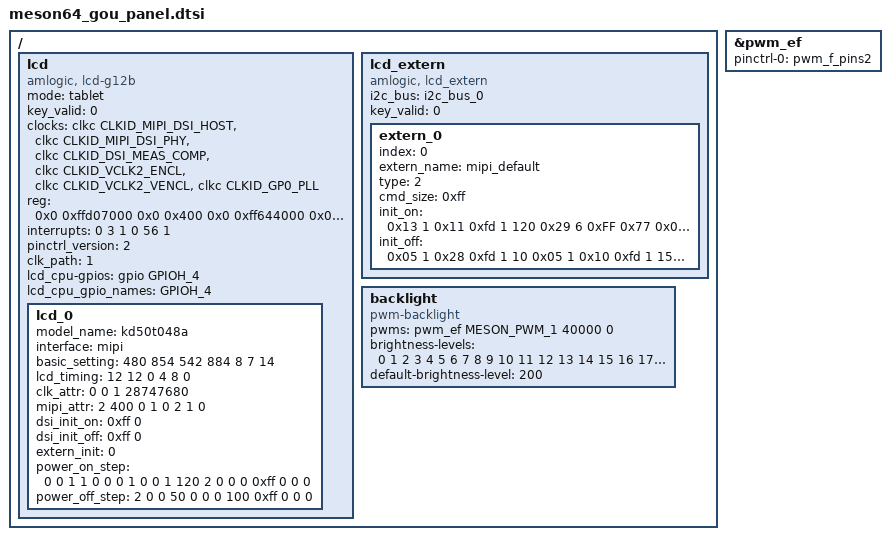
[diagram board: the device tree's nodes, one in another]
/*
 * arch/arm64/boot/dts/amlogic/meson64_gou_panel.dtsi
 *
 * Copyright (C) 2021 Hardkernel Co,. Ltd. All rights reserved.
 *
 * This program is free software; you can redistribute it and/or modify
 * it under the terms of the GNU General Public License as published by
 * the Free Software Foundation; either version 2 of the License, or
 * (at your option) any later version.
 *
 * This program is distributed in the hope that it will be useful, but WITHOUT
 * ANY WARRANTY; without even the implied warranty of MERCHANTABILITY or
 * FITNESS FOR A PARTICULAR PURPOSE.  See the GNU General Public License for
 * more details.
 *
 */

/ {
	lcd{
		compatible = "amlogic, lcd-g12b";
		mode = "tablet";
		status = "okay";
		key_valid = <0>;
		clocks = <&clkc CLKID_MIPI_DSI_HOST
			&clkc CLKID_MIPI_DSI_PHY
			&clkc CLKID_DSI_MEAS_COMP
			&clkc CLKID_VCLK2_ENCL
			&clkc CLKID_VCLK2_VENCL
			&clkc CLKID_GP0_PLL>;
		clock-names = "dsi_host_gate",
			"dsi_phy_gate",
			"dsi_meas",
			"encl_top_gate",
			"encl_int_gate",
			"gp0_pll";
		reg = <0x0 0xffd07000 0x0 0x400    /* dsi_host */
			0x0 0xff644000 0x0 0x200>; /* dsi_phy */
		interrupts = <0 3 1
			0 56 1>;
		interrupt-names = "vsync","vsync2";
		pinctrl_version = <2>; /* for uboot */
		clk_path = <1>; /* default gp0 pll */

		/* power type:
		 *    (0=cpu_gpio, 1=pmu_gpio, 2=signal,3=extern, 0xff=ending)
		 * power index:
		 *    (point gpios_index, or extern_index,0xff=invalid)
		 * power value:(0=output low, 1=output high, 2=input)
		 * power delay:(unit in ms)
		 */
		lcd_cpu-gpios = <&gpio GPIOH_4 GPIO_ACTIVE_HIGH>;
		lcd_cpu_gpio_names = "GPIOH_4";

		lcd_0{
			model_name = "kd50t048a";
				/*interface(ttl,lvds,mipi)*/
			interface = "mipi";
			basic_setting = <
				480 854 /*h_active, v_active*/
				542 884 /*h_period=hfp+hbp+hsync-len, v_period=vfp+vbp+vsync-len*/
				8 /*lcd_bits*/
				7 14>; /*screen_widht, screen_height*/
			lcd_timing = <
				12 12 0 /*hs_width(hsync-len),hs_bp,hs_pol*/
				4 8 0>; /*vs_width(vsync-len),vs_bp,vs_pol*/
			clk_attr = <0 /*fr_adj_type(0=clock,1=htotal,2=vtotal)*/
				0 /*clk_ss_level*/
				1 /*clk_auto_generate*/
				28747680>; /*pixel_clk(unit in Hz) h_period*v_period*60 */
			mipi_attr = <2 /*lane_num*/
				400 /*bit_rate_max(MHz)*/
				0 /*factor(*100, default 0 for auto)*/
				1 /*operation_mode_init(0=video, 1=command)*/
				0 /*operation_mode_display(0=video, 1=command)*/
				2 /*
				   *video_mode_type
				   *(0=sync_pulse,1=sync_event,2=burst)
				   */
				1 /*clk_always_hs(0=disable,1=enable)*/
				0>; /*phy_switch(0=auto,1=standard,2=slow)*/
				/* dsi_init: data_type, num, data... */
			dsi_init_on = <0xff 0>; /* ending flag */
			dsi_init_off = <0xff 0>; /* ending flag */
				/* extern_init: 0xff for invalid */
			extern_init = <0>;
				/* power step: type,index,value,delay(ms) */
			power_on_step = <0 0 1 1
					0 0 0 1
					0 0 1 120
					2 0 0 0
					0xff 0 0 0>;
			power_off_step = <2 0 0 50
					0 0 0 100
					0xff 0 0 0>;
		};
	};

	lcd_extern{
		compatible = "amlogic, lcd_extern";
		status = "okay";
		i2c_bus = "i2c_bus_0";
		key_valid = <0>;

		extern_0{
			index = <0>;
			extern_name = "mipi_default";/*ST7701*/
			status = "okay";
			type = <2>; /* 0=i2c, 1=spi, 2=mipi */
			cmd_size = <0xff>;
			init_on = <
				0x13  1 0x11
				0xfd  1 120	/* delay (ms) */

				0x29  6 0xFF 0x77 0x01 0x00 0x00 0x10
				0x29  3 0xC0 0xE9 0x03
				0x29  3 0xC1 0x11 0x02
				0x29  3 0xC2 0x31 0x08
				0x23  2 0xCC 0x10
				0x29 17 0xB0 0x00 0x0D 0x14 0x0D 0x10 0x05 0x02 0x08
				        0x08 0x1E 0x05 0x13 0x11 0xA3 0x29 0x18
				0x29 17 0xB1 0x00 0x0C 0x14 0x0C 0x10 0x05 0x03 0x08
				        0x07 0x20 0x05 0x13 0x11 0xA4 0x29 0x18
				0x29  6 0xFF 0x77 0x01 0x00 0x00 0x11
				0x23  2 0xB0 0x6C
				0x23  2 0xB1 0x43
				0x23  2 0xB2 0x07
				0x23  2 0xB3 0x80
				0x23  2 0xB5 0x47
				0x23  2 0xB7 0x85
				0x23  2 0xB8 0x20
				0x23  2 0xB9 0x10
				0x23  2 0xC1 0x78
				0x23  2 0xC3 0x78
				0x23  2 0xD0 0x88
				0xfd  1 250 /* delay (ms) */

				0x29  4 0xE0 0x00 0x00 0x02
				0x29 12 0xE1 0x08 0x00 0x0A 0x00 0x07 0x00 0x09 0x00
					0x00 0x33 0x33
				0x29 15 0xE2 0x00 0x00 0x00 0x00 0x00 0x00 0x00 0x00 
					0x00 0x00 0x00 0x00 0x00 0x00
				0x29  5 0xE3 0x00 0x00 0x33 0x33
				0x29  3 0xE4 0x44 0x44
				0x29 17 0xE5 0x0E 0x60 0xA0 0xA0 0x10 0x60 0xA0 0xA0
				        0x0A 0x60 0xA0 0xA0 0x0C 0x60 0xA0 0xA0
				0x29  5 0xE6 0x00 0x00 0x33 0x33
				0x29  3 0xE7 0x44 0x44
				0x29 17 0xE8 0x0D 0x60 0xA0 0xA0 0x0F 0x60 0xA0 0xA0
				        0x09 0x60 0xA0 0xA0 0x0B 0x60 0xA0 0xA0
				0x29  8 0xEB 0x02 0x01 0xE4 0xE4 0x44 0x00 0x40
				0x29  3 0xEC 0x02 0x01
				0x29 17 0xED 0xAB 0x89 0x76 0x54 0x01 0xFF 0xFF 0xFF
				        0xFF 0xFF 0xFF 0x10 0x45 0x67 0x98 0xBA
				0x29  6 0xFF 0x77 0x01 0x00 0x00 0x00
				0x23  2 0x3A 0x70
				0x23  2 0x53 0xEC
				0x23  2 0x55 0xB3
				0x23  2 0x5E 0xFF
				0x13  1 0x29
				0xfd  1 50	/* delay (ms) */
				0xff  0>; /*ending*/
			init_off = <
				0x05 1 0x28 /* display off */
				0xfd 1 10   /* delay 10ms */
				0x05 1 0x10 /* sleep in */
				0xfd 1 150  /* delay 150ms */
				0xff 0>;    /*ending*/
		};
	};
	backlight: backlight {
		compatible = "pwm-backlight";
		pwms = <&pwm_ef MESON_PWM_1 40000 0>;
		brightness-levels = <
			  0   1   2   3   4   5   6   7
			  8   9  10  11  12  13  14  15
			 16  17  18  19  20  21  22  23
			 24  25  26  27  28  29  30  31
			 32  33  34  35  36  37  38  39
			 40  41  42  43  44  45  46  47
			 48  49  50  51  52  53  54  55
			 56  57  58  59  60  61  62  63
			 64  65  66  67  68  69  70  71
			 72  73  74  75  76  77  78  79
			 80  81  82  83  84  85  86  87
			 88  89  90  91  92  93  94  95
			 96  97  98  99 100 101 102 103
			104 105 106 107 108 109 110 111
			112 113 114 115 116 117 118 119
			120 121 122 123 124 125 126 127
			128 129 130 131 132 133 134 135
			136 137 138 139 140 141 142 143
			144 145 146 147 148 149 150 151
			152 153 154 155 156 157 158 159
			160 161 162 163 164 165 166 167
			168 169 170 171 172 173 174 175
			176 177 178 179 180 181 182 183
			184 185 186 187 188 189 190 191
			192 193 194 195 196 197 198 199
			200 201 202 203 204 205 206 207
			208 209 210 211 212 213 214 215
			216 217 218 219 220 221 222 223
			224 225 226 227 228 229 230 231
			232 233 234 235 236 237 238 239
			240 241 242 243 244 245 246 247
			248 249 250 251 252 253 254 255>;
		default-brightness-level = <200>;
	};
};/* end of panel */

&pwm_ef {
	status = "okay";
	pinctrl-names = "pwm_pins";
	pinctrl-0 = <&pwm_f_pins2>;
};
